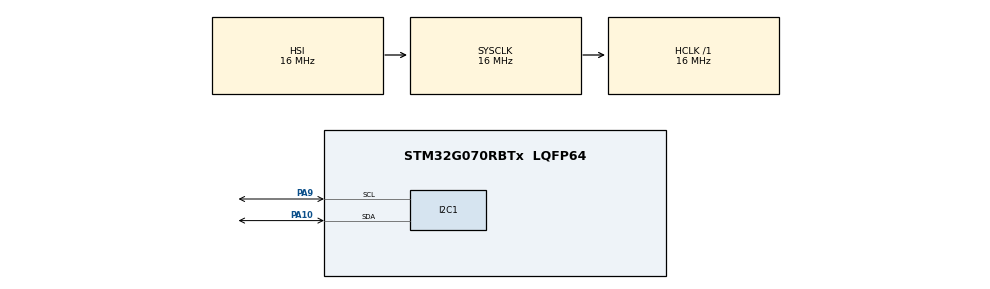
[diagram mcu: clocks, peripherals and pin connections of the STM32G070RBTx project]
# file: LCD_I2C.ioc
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Mcu.Family=STM32G0
Mcu.Name=STM32G070RBTx
Mcu.Package=LQFP64
PA10.Mode=I2C
PA10.Signal=I2C1_SDA
PA9.Mode=I2C
PA9.Signal=I2C1_SCL
ProjectManager.HeapSize=0x200
ProjectManager.StackSize=0x400
ProjectManager.TargetToolchain=STM32CubeIDE
RCC.AHBFreq_Value=16000000
RCC.CortexFreq_Value=16000000
RCC.EXTERNAL_CLOCK_VALUE=12288000
RCC.HCLKFreq_Value=16000000
RCC.HSE_VALUE=8000000
RCC.HSI_VALUE=16000000
RCC.SYSCLKFreq_VALUE=16000000
RCC.VCOOutputFreq_Value=128000000
board=NUCLEO-G070RB

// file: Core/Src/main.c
/* USER CODE BEGIN Header */
/**
  ******************************************************************************
  * @file           : main.c
  * @brief          : Main program body
  ******************************************************************************
  * @attention
  *
  * Copyright (c) 2023 STMicroelectronics.
  * All rights reserved.
  *
  * This software is licensed under terms that can be found in the LICENSE file
  * in the root directory of this software component.
  * If no LICENSE file comes with this software, it is provided AS-IS.
  *
  ******************************************************************************
  */
/* USER CODE END Header */
#include "main.h"

/* USER CODE BEGIN Includes */

#include "lcd_i2c.h"
#include "wire.h"

/* USER CODE END Includes */

I2C_HandleTypeDef hi2c1;

void SystemClock_Config(void);
static void MX_GPIO_Init(void);
static void MX_I2C1_Init(void);

int main(void)
{

  /* MCU Configuration--------------------------------------------------------*/

  /* Reset of all peripherals, Initializes the Flash interface and the Systick. */
  HAL_Init();

  /* Configure the system clock */
  SystemClock_Config();

  /* Initialize all configured peripherals */
  MX_GPIO_Init();
  MX_I2C1_Init();
  /* USER CODE BEGIN 2 */
  // Initialize LCD
      LCD_Init();

      // Clear the LCD display
      LCD_Clear();

      // Set cursor to the first line, first column
      LCD_SetCursor(0, 0);

      // Print "Hello, World!" on the LCD
      LCD_Print("Hello, World!");

  /* USER CODE END 2 */

  /* Infinite loop */
  while (1)
  {

  }
}

void SystemClock_Config(void)
{
  RCC_OscInitTypeDef RCC_OscInitStruct = {0};
  RCC_ClkInitTypeDef RCC_ClkInitStruct = {0};

  /** Configure the main internal regulator output voltage
  */
  HAL_PWREx_ControlVoltageScaling(PWR_REGULATOR_VOLTAGE_SCALE1);

  /** Initializes the RCC Oscillators according to the specified parameters
  * in the RCC_OscInitTypeDef structure.
  */
  RCC_OscInitStruct.OscillatorType = RCC_OSCILLATORTYPE_HSI;
  RCC_OscInitStruct.HSIState = RCC_HSI_ON;
  RCC_OscInitStruct.HSIDiv = RCC_HSI_DIV1;
  RCC_OscInitStruct.HSICalibrationValue = RCC_HSICALIBRATION_DEFAULT;
  RCC_OscInitStruct.PLL.PLLState = RCC_PLL_NONE;
  if (HAL_RCC_OscConfig(&RCC_OscInitStruct) != HAL_OK)
  {
    Error_Handler();
  }

  /** Initializes the CPU, AHB and APB buses clocks
  */
  RCC_ClkInitStruct.ClockType = RCC_CLOCKTYPE_HCLK|RCC_CLOCKTYPE_SYSCLK
                              |RCC_CLOCKTYPE_PCLK1;
  RCC_ClkInitStruct.SYSCLKSource = RCC_SYSCLKSOURCE_HSI;
  RCC_ClkInitStruct.AHBCLKDivider = RCC_SYSCLK_DIV1;
  RCC_ClkInitStruct.APB1CLKDivider = RCC_HCLK_DIV1;

  if (HAL_RCC_ClockConfig(&RCC_ClkInitStruct, FLASH_LATENCY_0) != HAL_OK)
  {
    Error_Handler();
  }
}

static void MX_I2C1_Init(void)
{

  /* USER CODE BEGIN I2C1_Init 1 */
	// __HAL_RCC_I2C1_CLK_ENABLE();

  /* USER CODE END I2C1_Init 1 */
  hi2c1.Instance = I2C1;
  hi2c1.Init.Timing = 0x00303D5B;
  hi2c1.Init.OwnAddress1 = 0;
  hi2c1.Init.AddressingMode = I2C_ADDRESSINGMODE_7BIT;
  hi2c1.Init.DualAddressMode = I2C_DUALADDRESS_DISABLE;
  hi2c1.Init.OwnAddress2 = 0;
  hi2c1.Init.OwnAddress2Masks = I2C_OA2_NOMASK;
  hi2c1.Init.GeneralCallMode = I2C_GENERALCALL_DISABLE;
  hi2c1.Init.NoStretchMode = I2C_NOSTRETCH_DISABLE;
  if (HAL_I2C_Init(&hi2c1) != HAL_OK)
  {
    Error_Handler();
  }

  /** Configure Analogue filter
  */
  if (HAL_I2CEx_ConfigAnalogFilter(&hi2c1, I2C_ANALOGFILTER_ENABLE) != HAL_OK)
  {
    Error_Handler();
  }

  /** Configure Digital filter
  */
  if (HAL_I2CEx_ConfigDigitalFilter(&hi2c1, 0) != HAL_OK)
  {
    Error_Handler();
  }

}

static void MX_GPIO_Init(void)
{

  /* GPIO Ports Clock Enable */
  __HAL_RCC_GPIOA_CLK_ENABLE();

}

void Error_Handler(void)
{
  /* USER CODE BEGIN Error_Handler_Debug */
  /* User can add his own implementation to report the HAL error return state */
  __disable_irq();
  while (1)
  {
	  // Clear the LCD display
	        LCD_Clear();

	        // Set cursor to the first line, first column
	        LCD_SetCursor(1, 1);

	        // Print "Hello, World!" on the LCD
	        LCD_Print("Hello, World!");
  }
  /* USER CODE END Error_Handler_Debug */
}
